# CY8C5467LTI_LP003 register map
File version: 0.1
CY8C54LP
Registers are 8-bit, read-write, no defined reset value unless marked. A register's access mark holds for its fields unless they carry their own. Offsets are from the block's base; lines under a group give offsets from that group; [hi:lo] are bit positions; {n}, {i} and the like mark numbered series; 'fields as' and 'values as' point back to an identical list; <NAME> marks a mode.

## Memory map
0x00000000 ESP_UART — UART
0x00000000 PSoC_UART — UART
0x00000000 XBee_UART — UART
0x00000000 I2C
0x00000000 USBUART — USBFS
0x00000000 CSD — CapSense
0x00000000 CSD_IdacCH0
0x00000000 CSD_CompCH0
0x40006477 UART_Reg

## ESP_UART — UART
Base 0x00000000
0x40006420 RX_ESP_UART_RX_ADDRESS1 — RX Address1 Register
0x40006430 RX_ESP_UART_RX_ADDRESS2 — RX Address2 Register
0x40006440 RX_ESP_UART_RX_DATA — RX Data Register
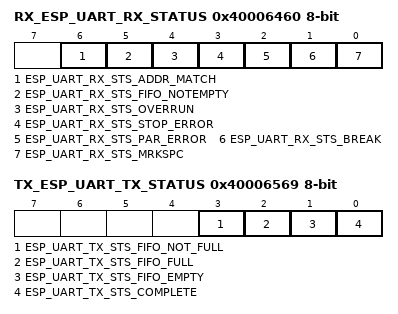
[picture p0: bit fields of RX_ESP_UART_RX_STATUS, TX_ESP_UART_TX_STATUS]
0x40006460 RX_ESP_UART_RX_STATUS — RX status register
  [6] ESP_UART_RX_STS_ADDR_MATCH ro, [5] ESP_UART_RX_STS_FIFO_NOTEMPTY ro, [4] ESP_UART_RX_STS_OVERRUN ro, [3] ESP_UART_RX_STS_STOP_ERROR ro, [2] ESP_UART_RX_STS_PAR_ERROR ro, [1] ESP_UART_RX_STS_BREAK ro, [0] ESP_UART_RX_STS_MRKSPC ro
0x40006548 TX_ESP_UART_TX_DATA — TX Data Register
0x40006569 TX_ESP_UART_TX_STATUS — TX status register
  [3] ESP_UART_TX_STS_FIFO_NOT_FULL ro, [2] ESP_UART_TX_STS_FIFO_FULL ro, [1] ESP_UART_TX_STS_FIFO_EMPTY ro, [0] ESP_UART_TX_STS_COMPLETE ro

## PSoC_UART — UART
Base 0x00000000
0x40006426 RX_PSoC_UART_RX_ADDRESS1 — RX Address1 Register
0x40006436 RX_PSoC_UART_RX_ADDRESS2 — RX Address2 Register
0x40006446 RX_PSoC_UART_RX_DATA — RX Data Register
0x40006449 TX_PSoC_UART_TX_DATA — TX Data Register
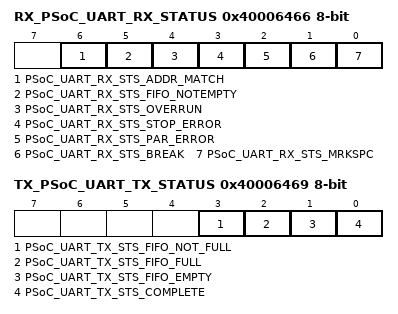
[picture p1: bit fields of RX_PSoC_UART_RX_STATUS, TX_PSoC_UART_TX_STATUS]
0x40006466 RX_PSoC_UART_RX_STATUS — RX status register
  [6] PSoC_UART_RX_STS_ADDR_MATCH ro, [5] PSoC_UART_RX_STS_FIFO_NOTEMPTY ro, [4] PSoC_UART_RX_STS_OVERRUN ro, [3] PSoC_UART_RX_STS_STOP_ERROR ro, [2] PSoC_UART_RX_STS_PAR_ERROR ro, [1] PSoC_UART_RX_STS_BREAK ro, [0] PSoC_UART_RX_STS_MRKSPC ro
0x40006469 TX_PSoC_UART_TX_STATUS — TX status register
  [3] PSoC_UART_TX_STS_FIFO_NOT_FULL ro, [2] PSoC_UART_TX_STS_FIFO_FULL ro, [1] PSoC_UART_TX_STS_FIFO_EMPTY ro, [0] PSoC_UART_TX_STS_COMPLETE ro

## XBee_UART — UART
Base 0x00000000
0x40006427 RX_XBee_UART_RX_ADDRESS1 — RX Address1 Register
0x40006437 RX_XBee_UART_RX_ADDRESS2 — RX Address2 Register
0x40006447 RX_XBee_UART_RX_DATA — RX Data Register
0x4000644F TX_XBee_UART_TX_DATA — TX Data Register
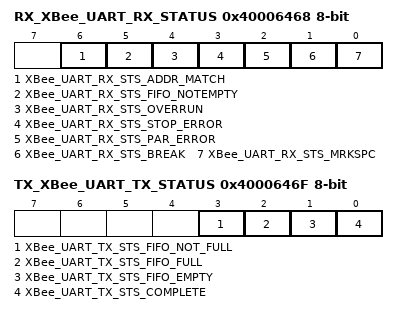
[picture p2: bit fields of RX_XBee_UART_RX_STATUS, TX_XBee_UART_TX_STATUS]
0x40006468 RX_XBee_UART_RX_STATUS — RX status register
  [6] XBee_UART_RX_STS_ADDR_MATCH ro, [5] XBee_UART_RX_STS_FIFO_NOTEMPTY ro, [4] XBee_UART_RX_STS_OVERRUN ro, [3] XBee_UART_RX_STS_STOP_ERROR ro, [2] XBee_UART_RX_STS_PAR_ERROR ro, [1] XBee_UART_RX_STS_BREAK ro, [0] XBee_UART_RX_STS_MRKSPC ro
0x4000646F TX_XBee_UART_TX_STATUS — TX status register
  [3] XBee_UART_TX_STS_FIFO_NOT_FULL ro, [2] XBee_UART_TX_STS_FIFO_FULL ro, [1] XBee_UART_TX_STS_FIFO_EMPTY ro, [0] XBee_UART_TX_STS_COMPLETE ro

## UART_Reg
Base 0x40006477
0x00 UART_Reg_CONTROL_REG

## USBUART — USBFS
Base 0x00000000
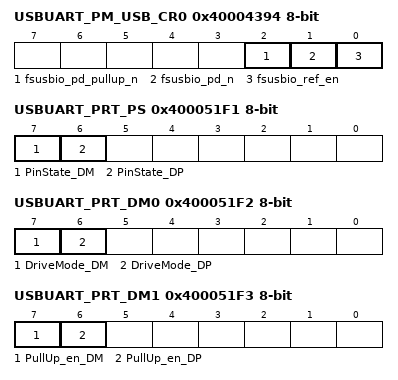
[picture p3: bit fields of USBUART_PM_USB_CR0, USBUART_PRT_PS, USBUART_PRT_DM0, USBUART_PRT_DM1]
0x40004394 USBUART_PM_USB_CR0 — USB Power Mode Control Register 0
  [2] fsusbio_pd_pullup_n, [1] fsusbio_pd_n, [0] fsusbio_ref_en
0x400043A5 USBUART_PM_ACT_CFG — Active Power Mode Configuration Register
0x400043B5 USBUART_PM_STBY_CFG — Standby Power Mode Configuration Register
0x400051F1 USBUART_PRT_PS — Port Pin State Register
  [7] PinState_DM ro, [6] PinState_DP ro
0x400051F2 USBUART_PRT_DM0 — Port Drive Mode Register
  [7] DriveMode_DM, [6] DriveMode_DP
0x400051F3 USBUART_PRT_DM1 — Port Drive Mode Register
  [7] PullUp_en_DM, [6] PullUp_en_DP
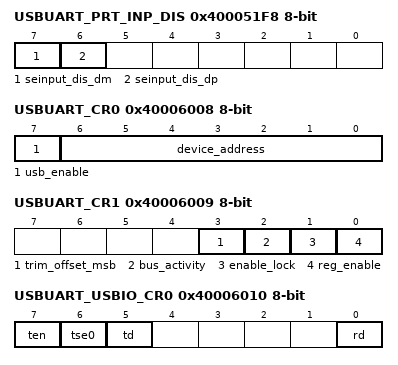
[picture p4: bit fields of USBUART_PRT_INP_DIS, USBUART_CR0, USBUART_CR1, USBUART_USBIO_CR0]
0x400051F8 USBUART_PRT_INP_DIS — Input buffer disable override
  [7] seinput_dis_dm, [6] seinput_dis_dp
0x40006000 USBUART_EP0_DR0 — bmRequestType
0x40006001 USBUART_EP0_DR1 — bRequest
0x40006002 USBUART_EP0_DR2 — wValueLo
0x40006003 USBUART_EP0_DR3 — wValueHi
0x40006004 USBUART_EP0_DR4 — wIndexLo
0x40006005 USBUART_EP0_DR5 — wIndexHi
0x40006006 USBUART_EP0_DR6 — lengthLo
0x40006007 USBUART_EP0_DR7 — lengthHi
0x40006008 USBUART_CR0 — USB Control Register 0
  [7] usb_enable, [6:0] device_address ro
0x40006009 USBUART_CR1 — USB Control Register 1
  [3] trim_offset_msb, [2] bus_activity, [1] enable_lock, [0] reg_enable
{0x40005FFE+0x10*i} USBUART_SIE_EP{i}_CR0 (i=1..8) — The Endpoint{i} Control Register
0x40006010 USBUART_USBIO_CR0 — USBIO Control Register 0
  [7] ten, [6] tse0, [5] td, [0] rd ro
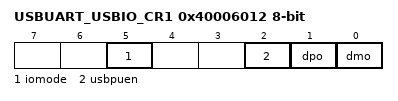
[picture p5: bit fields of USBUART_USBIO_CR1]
0x40006012 USBUART_USBIO_CR1 — USBIO Control Register 1
  [5] iomode, [2] usbpuen, [1] dpo ro, [0] dmo ro
0x4000608C USBUART_BUF_SIZE — Dedicated Endpoint Buffer Size Register
0x4000608E USBUART_EP_ACTIVE — Endpoint Active Indication Register
0x4000608F USBUART_EP_TYPE — Endpoint Type (IN/OUT) Indication
0x4000609D USBUART_USB_CLK_EN — USB Block Clock Enable Register
